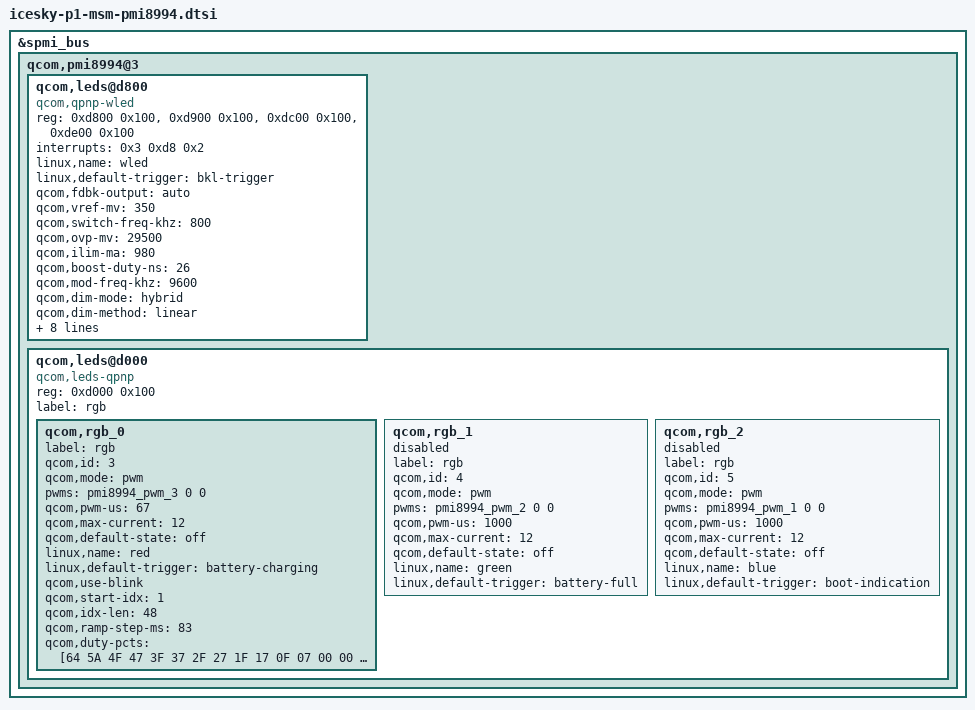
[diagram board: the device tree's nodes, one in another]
/* Copyright (c) 2014, The Linux Foundation. All rights reserved.
 *
 * This program is free software; you can redistribute it and/or modify
 * it under the terms of the GNU General Public License version 2 and
 * only version 2 as published by the Free Software Foundation.
 *
 * This program is distributed in the hope that it will be useful,
 * but WITHOUT ANY WARRANTY; without even the implied warranty of
 * MERCHANTABILITY or FITNESS FOR A PARTICULAR PURPOSE.  See the
 * GNU General Public License for more details.
 *
 * It inherits from msm-pmi8994.dtsi
 */

&spmi_bus {
	qcom,pmi8994@3 {
		qcom,leds@d800 {
			compatible = "qcom,qpnp-wled";
			reg = <0xd800 0x100>,
				<0xd900 0x100>,
				<0xdc00 0x100>,
				<0xde00 0x100>;
			reg-names = "qpnp-wled-ctrl-base",
					"qpnp-wled-sink-base",
					"qpnp-wled-ibb-base",
					"qpnp-wled-lab-base";
			interrupts = <0x3 0xd8 0x2>;
			interrupt-names = "sc-irq";
			status = "okay";
			linux,name = "wled";
			linux,default-trigger = "bkl-trigger";
			qcom,fdbk-output = "auto";
			qcom,vref-mv = <350>;
			qcom,switch-freq-khz = <800>;
			qcom,ovp-mv = <29500>;
			qcom,ilim-ma = <980>;
			qcom,boost-duty-ns = <26>;
			qcom,mod-freq-khz = <9600>;
			qcom,dim-mode = "hybrid";
			qcom,dim-method = "linear";
			qcom,hyb-thres = <625>;
			qcom,sync-dly-us = <800>;
			qcom,fs-curr-ua = <20000>;
			qcom,en-phase-stag;
			qcom,ibb-pwrup-dly = <8>;
			qcom,led-strings-list = [00 01];
			qcom,en-ext-pfet-sc-pro;
			qcom,en-cabc;
		};

		qcom,leds@d000 {
			compatible = "qcom,leds-qpnp";
			reg = <0xd000 0x100>;
			label = "rgb";
			status = "okay";

			qcom,rgb_0 {
				label = "rgb";
				qcom,id = <3>;
				qcom,mode = "pwm";
				pwms = <&pmi8994_pwm_3 0 0>;
				qcom,pwm-us = <67>;
				qcom,max-current = <12>;
				qcom,default-state = "off";
				linux,name = "red";
				linux,default-trigger = "battery-charging";
				qcom,use-blink;
				qcom,start-idx = <1>;
				qcom,idx-len = <48>;
				qcom,ramp-step-ms = <83>;
				qcom,duty-pcts = [64 5A 4F 47 3F 37 2F 27 1F 17 0F 07
					00 00 00 00 00 00 00 00 00 00 00 00 00 00 00 00 00 00 00 00 00
					00 00 00 07 0F 17 1F 27 2F 37 3F 47 4F 5A 64];
			};

			qcom,rgb_1 {
				label = "rgb";
				qcom,id = <4>;
				qcom,mode = "pwm";
				pwms = <&pmi8994_pwm_2 0 0>;
				qcom,pwm-us = <1000>;
				qcom,max-current = <12>;
				qcom,default-state = "off";
				linux,name = "green";
				linux,default-trigger = "battery-full";
				status = "disabled";
			};

			qcom,rgb_2 {
				label = "rgb";
				qcom,id = <5>;
				qcom,mode = "pwm";
				pwms = <&pmi8994_pwm_1 0 0>;
				qcom,pwm-us = <1000>;
				qcom,max-current = <12>;
				qcom,default-state = "off";
				linux,name = "blue";
				linux,default-trigger = "boot-indication";
				status = "disabled";
			};
		};
	};
};
